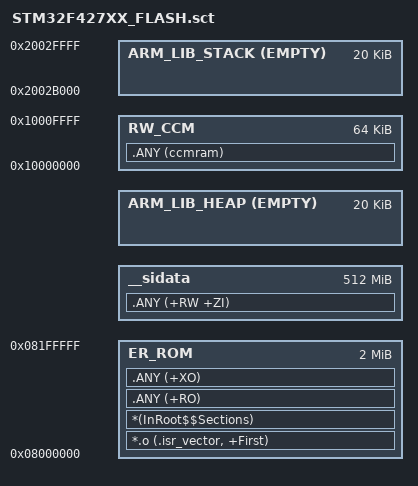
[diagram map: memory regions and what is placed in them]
#! armclang -E --target=arm-arm-none-eabi -mcpu=cortex-m4 -xc
; command above MUST be in first line (no comment above!)

; *************************************************************
; *** Scatter-Loading Description File for STM32F427IIHx  ***
; *** Generated for ARM Compiler 6 (armclang)              ***
; *** Based on CMSIS ARMCM4_ac6.sct                        ***
; *************************************************************

/*
;-------- <<< Use Configuration Wizard in Context Menu >>> -------------------
*/

/*--------------------- Flash Configuration ----------------------------------
; <h> Flash Configuration
;   <o0> Flash Base Address <0x0-0xFFFFFFFF:8>
;   <o1> Flash Size (in Bytes) <0x0-0xFFFFFFFF:8>
; </h>
 *----------------------------------------------------------------------------*/
#define __ROM_BASE      0x08000000   /* STM32F427 Flash起始地址: 0x08000000 */
#define __ROM_SIZE      0x00200000   /* 2MB Flash */

/*--------------------- Embedded RAM Configuration ---------------------------
; <h> RAM Configuration
;   <o0> RAM Base Address    <0x0-0xFFFFFFFF:8>
;   <o1> RAM Size (in Bytes) <0x0-0xFFFFFFFF:8>
; </h>
 *----------------------------------------------------------------------------*/
#define __RAM_BASE      0x20000000   /* 主RAM起始地址 */
#define __RAM_SIZE      0x00030000   /* 192KB 主RAM */

/*--------------------- CCM RAM Configuration -------------------------------
; <h> CCM RAM Configuration (STM32F4xx specific)
;   <o0> CCM RAM Base Address <0x0-0xFFFFFFFF:8>
;   <o1> CCM RAM Size (in Bytes) <0x0-0xFFFFFFFF:8>
; </h>
 *----------------------------------------------------------------------------*/
#define __CCM_BASE      0x10000000   /* CCM RAM起始地址 */
#define __CCM_SIZE      0x00010000   /* 64KB CCM RAM */

/*--------------------- Stack / Heap Configuration ---------------------------
; <h> Stack / Heap Configuration
;   <o0> Stack Size (in Bytes) <0x0-0xFFFFFFFF:8>
;   <o1> Heap Size (in Bytes) <0x0-0xFFFFFFFF:8>
; </h>
 *----------------------------------------------------------------------------*/
#define __STACK_SIZE    0x00005000   /* 20KB 栈 */
#define __HEAP_SIZE     0x00005000   /* 20KB 堆 */

/*
;------------- <<< end of configuration section >>> ---------------------------
*/

/*----------------------------------------------------------------------------
  User Stack & Heap boundary definition
 *----------------------------------------------------------------------------*/
#define __STACK_TOP    (__RAM_BASE + __RAM_SIZE)    /* starts at end of RAM */
#define __HEAP_BASE    (AlignExpr(+0, 8))           /* starts after RW_RAM section, 8 byte aligned */

/*----------------------------------------------------------------------------
  Scatter File Definitions definition
 *----------------------------------------------------------------------------*/
#define __RO_BASE       __ROM_BASE
#define __RO_SIZE       __ROM_SIZE

#define __RW_BASE       __RAM_BASE
#define __RW_SIZE      (__RAM_SIZE - __STACK_SIZE - __HEAP_SIZE)

/*----------------------------------------------------------------------------
  Load Region Definitions
 *----------------------------------------------------------------------------*/
LR_ROM __RO_BASE __RO_SIZE  {                       /* load region size_region */
  ER_ROM __RO_BASE __RO_SIZE  {                     /* load address = execution address */
   *.o (.isr_vector, +First)
   *(InRoot$$Sections)
   .ANY (+RO)
   .ANY (+XO)
  }

  /* Define symbols used by startup code */
  __sidata = Image$$ER_ROM$$Limit;

  RW_RAM __RW_BASE __RW_SIZE  {                     /* RW data */
   .ANY (+RW +ZI)
  }

#if __HEAP_SIZE > 0
  ARM_LIB_HEAP  __HEAP_BASE EMPTY  __HEAP_SIZE  {   /* Reserve empty region for heap */
  }
#endif

  ARM_LIB_STACK __STACK_TOP EMPTY -__STACK_SIZE {   /* Reserve empty region for stack */
  }
}

/* Define additional symbols for GCC compatibility */
__estack = __STACK_TOP;
Image$$RW_RAM$$Base = __RW_BASE;
Image$$RW_RAM$$Limit = __HEAP_BASE;

/*----------------------------------------------------------------------------
  CCM RAM Load Region (Separate region for CCM RAM)
 *----------------------------------------------------------------------------*/
LR_CCM __CCM_BASE __CCM_SIZE  {
  RW_CCM __CCM_BASE __CCM_SIZE  {
   .ANY (ccmram)
  }
}
